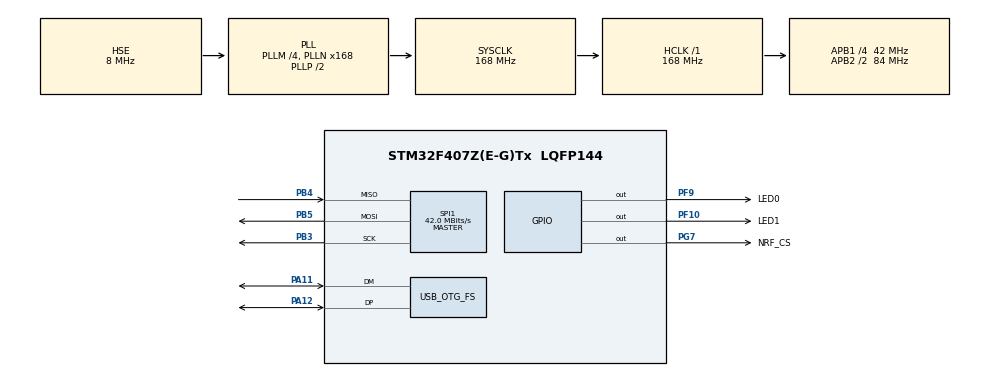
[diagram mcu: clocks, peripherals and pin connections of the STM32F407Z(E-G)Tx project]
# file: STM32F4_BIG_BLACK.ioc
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Mcu.Family=STM32F4
Mcu.Name=STM32F407Z(E-G)Tx
Mcu.Package=LQFP144
NVIC.OTG_FS_IRQn=true\:0\:0\:false\:false\:true\:false\:true
NVIC.PriorityGroup=NVIC_PRIORITYGROUP_4
PA11.Mode=Device_Only
PA11.Signal=USB_OTG_FS_DM
PA12.Mode=Device_Only
PA12.Signal=USB_OTG_FS_DP
PB3.Mode=Full_Duplex_Master
PB3.Signal=SPI1_SCK
PB4.Mode=Full_Duplex_Master
PB4.Signal=SPI1_MISO
PB5.Mode=Full_Duplex_Master
PB5.Signal=SPI1_MOSI
PF10.GPIO_Label=LED1
PF10.PinState=GPIO_PIN_SET
PF10.Signal=GPIO_Output
PF9.GPIO_Label=LED0
PF9.Signal=GPIO_Output
PG7.GPIO_Label=NRF_CS
PG7.PinState=GPIO_PIN_SET
PG7.Signal=GPIO_Output
PH0-OSC_IN.Mode=HSE-External-Oscillator
PH0-OSC_IN.Signal=RCC_OSC_IN
PH1-OSC_OUT.Mode=HSE-External-Oscillator
PH1-OSC_OUT.Signal=RCC_OSC_OUT
ProjectManager.HeapSize=0x200
ProjectManager.StackSize=0x400
ProjectManager.TargetToolchain=STM32CubeIDE
RCC.48MHZClocksFreq_Value=48000000
RCC.AHBFreq_Value=168000000
RCC.APB1CLKDivider=RCC_HCLK_DIV4
RCC.APB1Freq_Value=42000000
RCC.APB1TimFreq_Value=84000000
RCC.APB2CLKDivider=RCC_HCLK_DIV2
RCC.APB2Freq_Value=84000000
RCC.APB2TimFreq_Value=168000000
RCC.CortexFreq_Value=168000000
RCC.HCLKFreq_Value=168000000
RCC.HSE_VALUE=8000000
RCC.HSI_VALUE=16000000
RCC.LSE_VALUE=32768
RCC.PLLM=4
RCC.PLLN=168
RCC.PLLQ=7
RCC.SYSCLKFreq_VALUE=168000000
RCC.SYSCLKSource=RCC_SYSCLKSOURCE_PLLCLK
RCC.VCOOutputFreq_Value=336000000
SPI1.CalculateBaudRate=42.0 MBits/s
SPI1.Direction=SPI_DIRECTION_2LINES
SPI1.Mode=SPI_MODE_MASTER
SPI1.VirtualType=VM_MASTER
USB_DEVICE.APP_TX_DATA_SIZE-CDC_FS=2048
USB_DEVICE.CLASS_NAME_FS=CDC
USB_DEVICE.VirtualMode-CDC_FS=Cdc
USB_DEVICE.VirtualModeFS=Cdc_FS
USB_OTG_FS.VirtualMode=Device_Only
VP_USB_DEVICE_VS_USB_DEVICE_CDC_FS.Mode=CDC_FS
board=custom

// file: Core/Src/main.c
/* USER CODE BEGIN Header */
/**
  ******************************************************************************
  * @file           : main.c
  * @brief          : Main program body
  ******************************************************************************
  * @attention
  *
  * <h2><center>&copy; Copyright (c) 2020 STMicroelectronics.
  * All rights reserved.</center></h2>
  *
  * This software component is licensed by ST under BSD 3-Clause license,
  * the "License"; You may not use this file except in compliance with the
  * License. You may obtain a copy of the License at:
  *                        opensource.org/licenses/BSD-3-Clause
  *
  ******************************************************************************
  */
/* USER CODE END Header */
#include "main.h"
#include "spi.h"
#include "usb_device.h"
#include "gpio.h"

void SystemClock_Config(void);
/* USER CODE BEGIN PFP */
#ifdef __GNUC__

 /* With GCC, small printf (option LD Linker->Libraries->Small printf

   set to 'Yes') calls __io_putchar() */

 #define PUTCHAR_PROTOTYPE int __io_putchar(int ch)

#else

 #define PUTCHAR_PROTOTYPE int fputc(int ch, FILE *f)

#endif /* __GNUC__ */
/* USER CODE END PFP */

int main(void)
{

  /* MCU Configuration--------------------------------------------------------*/

  /* Reset of all peripherals, Initializes the Flash interface and the Systick. */
  HAL_Init();

  /* Configure the system clock */
  SystemClock_Config();

  /* Initialize all configured peripherals */
  MX_GPIO_Init();
  MX_USB_DEVICE_Init();
  MX_SPI1_Init();
  /* USER CODE BEGIN 2 */

  initNrf();
  /* USER CODE END 2 */

  /* Infinite loop */
  /* USER CODE BEGIN WHILE */
  while (1)
  {
	  HAL_Delay(500);
	  HAL_GPIO_TogglePin(LED1_GPIO_Port, LED0_Pin);
	  HAL_GPIO_TogglePin(LED1_GPIO_Port, LED1_Pin);
//	  CDC_Transmit_FS(buffer, sizeof(buffer) -1);
	  for(uint8_t i =0; i < 10; ++i)
	  {
		  printf("REG(%d)=%d\n",i, nrfGetRegister(i));
	  }
    /* USER CODE END WHILE */

  }
}

void SystemClock_Config(void)
{
  RCC_OscInitTypeDef RCC_OscInitStruct = {0};
  RCC_ClkInitTypeDef RCC_ClkInitStruct = {0};

  /** Configure the main internal regulator output voltage
  */
  __HAL_RCC_PWR_CLK_ENABLE();
  __HAL_PWR_VOLTAGESCALING_CONFIG(PWR_REGULATOR_VOLTAGE_SCALE1);
  /** Initializes the RCC Oscillators according to the specified parameters
  * in the RCC_OscInitTypeDef structure.
  */
  RCC_OscInitStruct.OscillatorType = RCC_OSCILLATORTYPE_HSE;
  RCC_OscInitStruct.HSEState = RCC_HSE_ON;
  RCC_OscInitStruct.PLL.PLLState = RCC_PLL_ON;
  RCC_OscInitStruct.PLL.PLLSource = RCC_PLLSOURCE_HSE;
  RCC_OscInitStruct.PLL.PLLM = 4;
  RCC_OscInitStruct.PLL.PLLN = 168;
  RCC_OscInitStruct.PLL.PLLP = RCC_PLLP_DIV2;
  RCC_OscInitStruct.PLL.PLLQ = 7;
  if (HAL_RCC_OscConfig(&RCC_OscInitStruct) != HAL_OK)
  {
    Error_Handler();
  }
  /** Initializes the CPU, AHB and APB buses clocks
  */
  RCC_ClkInitStruct.ClockType = RCC_CLOCKTYPE_HCLK|RCC_CLOCKTYPE_SYSCLK
                              |RCC_CLOCKTYPE_PCLK1|RCC_CLOCKTYPE_PCLK2;
  RCC_ClkInitStruct.SYSCLKSource = RCC_SYSCLKSOURCE_PLLCLK;
  RCC_ClkInitStruct.AHBCLKDivider = RCC_SYSCLK_DIV1;
  RCC_ClkInitStruct.APB1CLKDivider = RCC_HCLK_DIV4;
  RCC_ClkInitStruct.APB2CLKDivider = RCC_HCLK_DIV2;

  if (HAL_RCC_ClockConfig(&RCC_ClkInitStruct, FLASH_LATENCY_5) != HAL_OK)
  {
    Error_Handler();
  }
}

/* USER CODE BEGIN 4 */
//PUTCHAR_PROTOTYPE
//{
//    //while(!(CDC_Transmit_FS((uint8_t*)&ch, 1) == USBD_OK));
//    CDC_Transmit_FS((uint8_t*)&ch, 1);
//    return ch;
//}
int _write(int file, char *ptr, int len)
{
	CDC_Transmit_FS(ptr, len);
}
/* USER CODE END 4 */

void Error_Handler(void)
{
}

/************************ (C) COPYRIGHT STMicroelectronics *****END OF FILE****/
